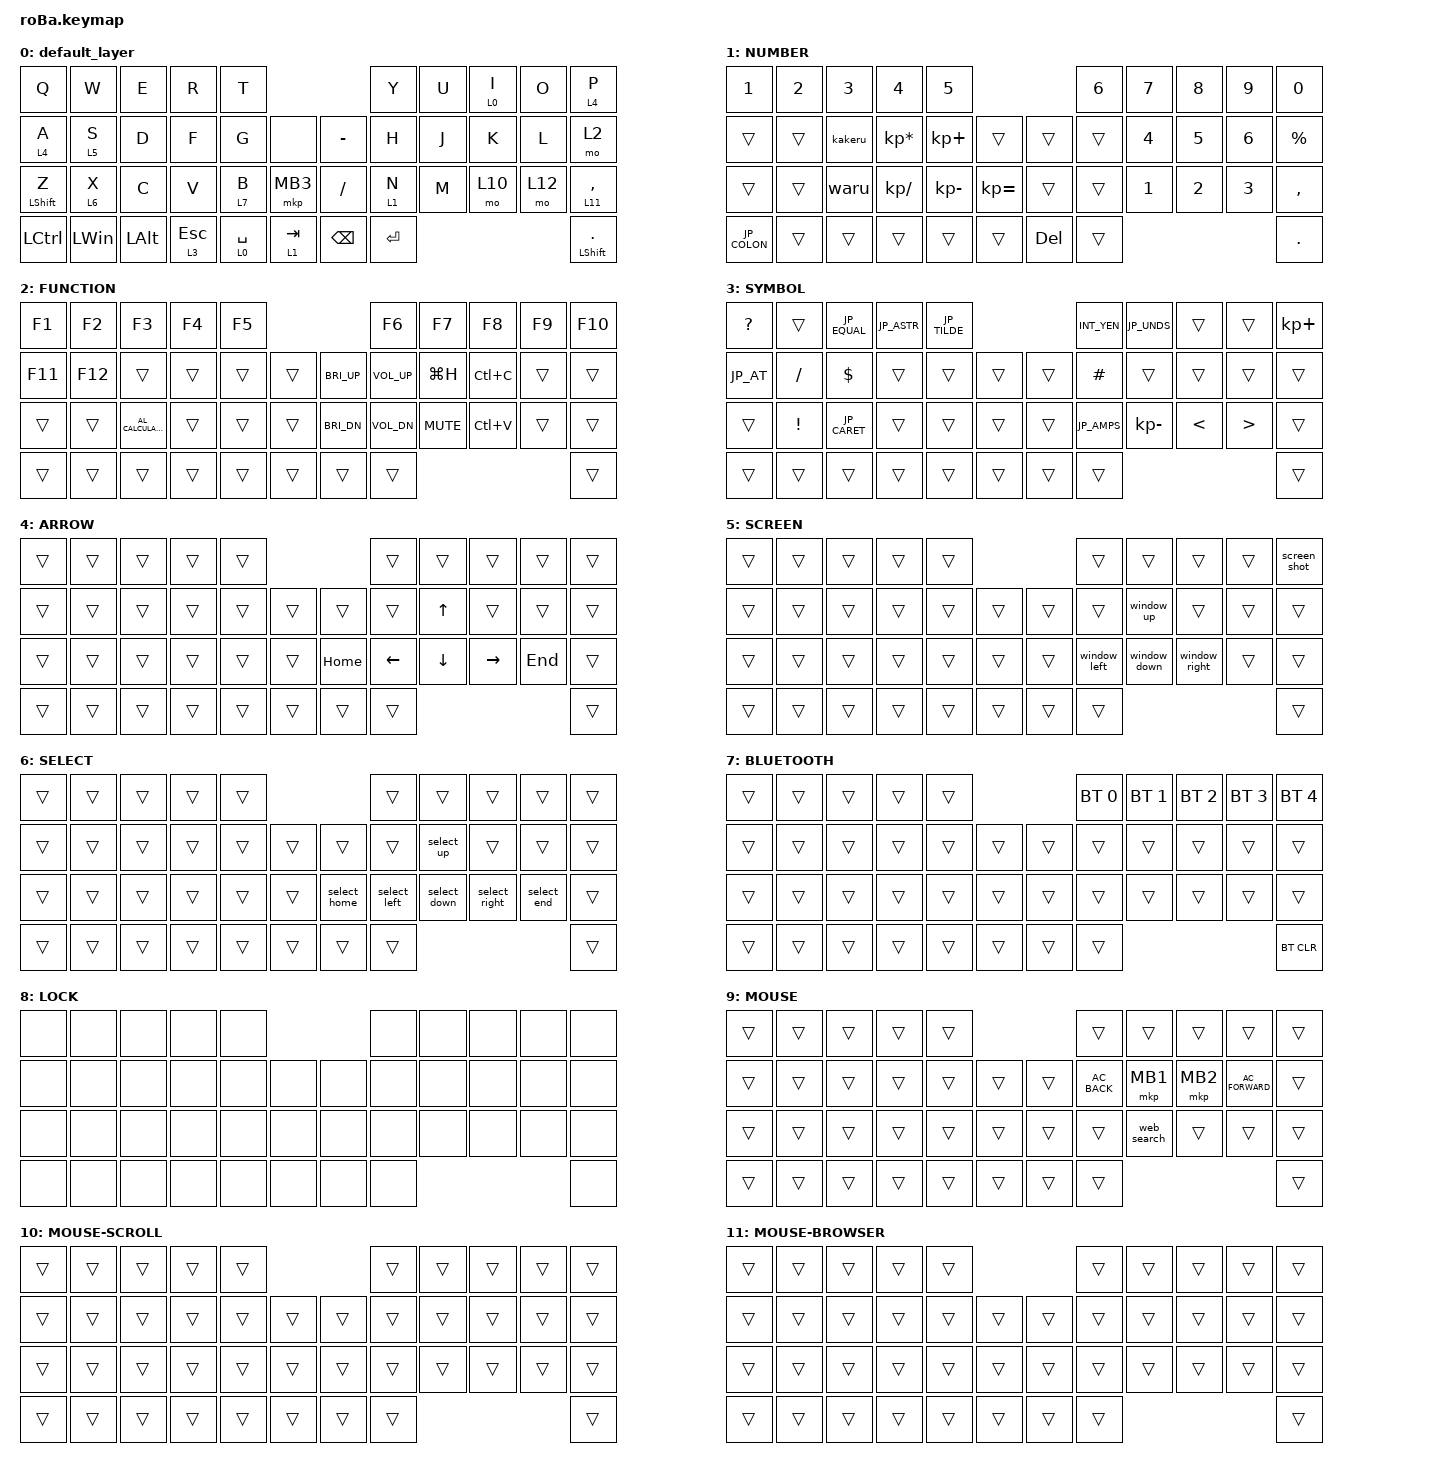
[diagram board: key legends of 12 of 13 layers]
#include <behaviors.dtsi>
#include <dt-bindings/zmk/bt.h>
#include <dt-bindings/zmk/keys.h>
#include <dt-bindings/zmk/pointing.h>

// OS側が日本語(JIS)キーボードとして認識している前提で、狙った記号が
// 出力されるように変換したキーコード。左辺の文字を出したい場合、
// 素直な同名キーコード(US配列前提)ではなく右辺を送る必要がある。

#define JP_AT      LEFT_BRACKET      // @
#define JP_DQT     LS(N2)            // "
#define JP_SQT     LS(N7)            // '
#define JP_GRAVE   LEFT_BRACE        // `
#define JP_COLON   SINGLE_QUOTE      // :
#define JP_ASTR    DOUBLE_QUOTES     // *
#define JP_CARET   EQUAL             // ^
#define JP_TILDE   PLUS              // ~
#define JP_EQUAL   UNDERSCORE        // =
#define JP_AMPS    CARET             // &
#define JP_UNDS    LS(INT_RO)        // _
#define JP_BSLH    INT_RO            // \ (ろキー)
#define JP_PIPE    LS(INT_YEN)       // |
#define JP_LBKT    RIGHT_BRACKET     // [
#define JP_RBKT    BACKSLASH         // ]
#define JP_LBRC    RIGHT_BRACE       // {
#define JP_RBRC    PIPE              // }
#define JP_LPAR    ASTERISK          // (
#define JP_RPAR    LEFT_PARENTHESIS  // )

&mt {
    flavor = "balanced";
    quick-tap-ms = <0>;
};

&trackball {
    scroll-layers = <10>;

    // arrows {
    //     layers = <3>;
    //     bindings =
    //         <&kp RIGHT_ARROW>,
    //         <&kp LEFT_ARROW>,
    //         <&kp UP_ARROW>,
    //         <&kp DOWN_ARROW>;
    //     tick = <10>;
    //     wait-ms = <5>;
    //     tap-ms = <5>;
    // };
};

/ {
    combos {
        compatible = "zmk,combos";

        child-lock {
            bindings = <&tog 8>;
            key-positions = <0 1 2 3>;
            timeout-ms = <100>;
        };

        single-quotes {
            bindings = <&kp JP_SQT>;
            key-positions = <5 6>;
            layers = <0 3>;
        };

        double-quotes {
            bindings = <&kp JP_DQT>;
            key-positions = <5 6 7>;
            layers = <0 3>;
        };

        back-quote {
            bindings = <&kp JP_GRAVE>;
            key-positions = <17 18>;
            layers = <0 3>;
        };

        brackets {
            bindings = <&brackets>;
            key-positions = <14 17>;
            layers = <0 3>;
        };

        parentheses {
            bindings = <&parentheses>;
            key-positions = <4 5>;
            layers = <0 3>;
        };

        braces {
            bindings = <&braces>;
            key-positions = <26 29>;
            layers = <0 3>;
        };

        muhenkan {
            bindings = <&kp INT_MUHENKAN>;
            key-positions = <27 26>;
            layers = <0>;
        };

        henkan {
            bindings = <&kp INT_HENKAN>;
            key-positions = <28 29>;
            layers = <0>;
        };

        mb3 {
            bindings = <&mkp MB3>;
            key-positions = <18 19>;
            layers = <9>;
        };

        semi-colon {
            bindings = <&kp SEMICOLON>;
            key-positions = <16 28>;
            layers = <0 3 1>;
        };

        colon {
            bindings = <&kp JP_COLON>;
            key-positions = <5 17>;
            layers = <0 3 1>;
        };

        back-slash {
            bindings = <&kp JP_BSLH>;
            key-positions = <20 32>;
            layers = <0 3 1>;
        };

        vertical-var {
            bindings = <&kp JP_PIPE>;
            key-positions = <31 19>;
            layers = <0 3 1>;
        };

        slash {
            bindings = <&kp SLASH>;
            key-positions = <18 30>;
            layers = <0 1 3>;
        };

        caret {
            bindings = <&kp JP_CARET>;
            key-positions = <17 6 19>;
            layers = <0 3 1>;
        };

        ctrl {
            bindings = <&kp RCTRL>;
            key-positions = <32 31>;
        };

        close {
            bindings = <&close>;
            key-positions = <36 3>;
        };
    };

    macros {
        brackets: brackets {
            compatible = "zmk,behavior-macro";
            #binding-cells = <0>;
            bindings = <&kp JP_LBKT &kp JP_RBKT &kp LEFT>;
            label = "BRACKETS";
        };

        braces: braces {
            compatible = "zmk,behavior-macro";
            #binding-cells = <0>;
            bindings = <&kp JP_LBRC &kp JP_RBRC &kp LEFT>;
            label = "BRACES";
        };

        parentheses: parentheses {
            compatible = "zmk,behavior-macro";
            #binding-cells = <0>;
            bindings = <&kp JP_LPAR &kp JP_RPAR &kp LEFT>;
            label = "PARENTHESES";
        };

        window_left: window_left {
            compatible = "zmk,behavior-macro";
            #binding-cells = <0>;
            bindings =
                <&macro_press>,
                <&kp LEFT_WIN>,
                <&macro_tap>,
                <&kp LEFT>,
                <&macro_release>,
                <&kp LEFT_WIN>;

            label = "WINDOW_LEFT";
        };

        window_right: window_right {
            compatible = "zmk,behavior-macro";
            #binding-cells = <0>;
            bindings =
                <&macro_press>,
                <&kp LEFT_WIN>,
                <&macro_tap>,
                <&kp RIGHT>,
                <&macro_release>,
                <&kp LEFT_WIN>;

            label = "WINDOW_RIGHT";
        };

        window_up: window_up {
            compatible = "zmk,behavior-macro";
            #binding-cells = <0>;
            bindings =
                <&macro_press>,
                <&kp LEFT_WIN>,
                <&macro_tap>,
                <&kp UP>,
                <&macro_release>,
                <&kp LEFT_WIN>;

            label = "WINDOW_UP";
        };

        window_down: window_down {
            compatible = "zmk,behavior-macro";
            #binding-cells = <0>;
            bindings =
                <&macro_press>,
                <&kp LEFT_WIN>,
                <&macro_tap>,
                <&kp DOWN>,
                <&macro_release>,
                <&kp LEFT_WIN>;

            label = "WINDOW_DOWN";
        };

        screen_shot: screen_shot {
            compatible = "zmk,behavior-macro";
            #binding-cells = <0>;
            bindings =
                <&macro_press>,
                <&kp LEFT_WIN &kp LEFT_SHIFT>,
                <&macro_tap>,
                <&kp S>,
                <&macro_release>,
                <&kp LEFT_WIN &kp LEFT_SHIFT>;

            label = "SCREEN_SHOT";
        };

        web_search: web_search {
            compatible = "zmk,behavior-macro";
            #binding-cells = <0>;

            // 右クリックメニューが開くまでの猶予を通常より長めに取る

            wait-ms = <150>;
            tap-ms = <30>;
            bindings =
                <&macro_press>,
                <&kp LSHIFT>,
                <&macro_tap>,
                <&kp F10>,
                <&macro_release>,
                <&kp LSHIFT>,
                <&macro_tap>,
                <&kp S>;

            label = "WEB_SEARCH";
        };

        vdesk_pin: vdesk_pin {
            compatible = "zmk,behavior-macro";
            #binding-cells = <0>;

            // タスクビューの描画・フォーカス確定を待つため、通常より長めに取る

            wait-ms = <200>;
            tap-ms = <30>;
            bindings =
                <&macro_tap>,
                <&kp LG(TAB) &kp LS(F10) &kp DOWN &kp DOWN &kp DOWN &kp RETURN>;

            label = "VDESK_PIN";
        };

        select_left: select_left {
            compatible = "zmk,behavior-macro";
            #binding-cells = <0>;
            bindings =
                <&macro_press>,
                <&kp LEFT_SHIFT>,
                <&macro_tap>,
                <&kp LEFT>,
                <&macro_release>,
                <&kp LEFT_SHIFT>;

            label = "SELECT_LEFT";
        };

        select_right: select_right {
            compatible = "zmk,behavior-macro";
            #binding-cells = <0>;
            bindings =
                <&macro_press>,
                <&kp LEFT_SHIFT>,
                <&macro_tap>,
                <&kp RIGHT>,
                <&macro_release>,
                <&kp LEFT_SHIFT>;

            label = "SELECT_RIGHT";
        };

        select_up: select_up {
            compatible = "zmk,behavior-macro";
            #binding-cells = <0>;
            bindings =
                <&macro_press>,
                <&kp LEFT_SHIFT>,
                <&macro_tap>,
                <&kp UP>,
                <&macro_release>,
                <&kp LEFT_SHIFT>;

            label = "SELECT_UP";
        };

        select_down: select_down {
            compatible = "zmk,behavior-macro";
            #binding-cells = <0>;
            bindings =
                <&macro_press>,
                <&kp LEFT_SHIFT>,
                <&macro_tap>,
                <&kp DOWN>,
                <&macro_release>,
                <&kp LEFT_SHIFT>;

            label = "SELECT_DOWN";
        };

        select_home: select_home {
            compatible = "zmk,behavior-macro";
            #binding-cells = <0>;
            bindings =
                <&macro_press>,
                <&kp LEFT_SHIFT>,
                <&macro_tap>,
                <&kp HOME>,
                <&macro_release>,
                <&kp LEFT_SHIFT>;

            label = "SELECT_HOME";
        };

        select_end: select_end {
            compatible = "zmk,behavior-macro";
            #binding-cells = <0>;
            bindings =
                <&macro_press>,
                <&kp LEFT_SHIFT>,
                <&macro_tap>,
                <&kp END>,
                <&macro_release>,
                <&kp LEFT_SHIFT>;

            label = "SELECT_END";
        };

        kakeru: kakeru {
            compatible = "zmk,behavior-macro";
            #binding-cells = <0>;
            bindings =
                <&macro_press>,
                <&kp LEFT_ALT>,
                <&macro_tap>,
                <&kp KP_N0 &kp KP_N2 &kp KP_N1 &kp KP_N5>,
                <&macro_release>,
                <&kp LEFT_ALT>;

            label = "KAKERU";
        };

        waru: waru {
            compatible = "zmk,behavior-macro";
            #binding-cells = <0>;
            bindings =
                <&macro_press>,
                <&kp LEFT_ALT>,
                <&macro_tap>,
                <&kp KP_N0 &kp KP_N2 &kp KP_N4 &kp KP_N7>,
                <&macro_release>,
                <&kp LEFT_ALT>;

            label = "WARU";
        };

        close: close {
            compatible = "zmk,behavior-macro";
            #binding-cells = <0>;
            bindings =
                <&macro_press>,
                <&kp LEFT_ALT>,
                <&macro_tap>,
                <&kp F4>,
                <&macro_release>,
                <&kp LEFT_ALT>;

            label = "CLOSE";
        };
    };

    keymap {
        compatible = "zmk,keymap";

        default_layer {
            bindings = <
&kp Q             &kp W         &kp E         &kp R         &kp T                                      &kp Y      &kp U  &lt 0 I  &kp O   &lt 4 P
&lt 4 A           &lt 5 S       &kp D         &kp F         &kp G        &none          &kp MINUS      &kp H      &kp J  &kp K    &kp L   &mo 2
&mt LEFT_SHIFT Z  &lt 6 X       &kp C         &kp V         &lt 7 B      &mkp MB3       &kp SLASH      &lt 1 N    &kp M  &mo 10   &mo 12  &lt 11 COMMA
&kp LCTRL         &kp LEFT_WIN  &kp LEFT_ALT  &lt 3 ESCAPE  &lt 0 SPACE  &lt 1 TAB      &kp BACKSPACE  &kp ENTER                          &mt LEFT_SHIFT PERIOD
            >;

            sensor-bindings = <&inc_dec_kp PG_UP PAGE_DOWN>;
        };

        NUMBER {
            bindings = <
&kp N1        &kp N2  &kp N3   &kp N4           &kp N5                                   &kp N6  &kp N7  &kp N8  &kp N9  &kp N0
&trans        &trans  &kakeru  &kp KP_MULTIPLY  &kp KP_PLUS   &trans            &trans   &trans  &kp N4  &kp N5  &kp N6  &kp PERCENT
&trans        &trans  &waru    &kp KP_SLASH     &kp KP_MINUS  &kp KP_EQUAL      &trans   &trans  &kp N1  &kp N2  &kp N3  &kp COMMA
&kp JP_COLON  &trans  &trans   &trans           &trans        &trans            &kp DEL  &trans                          &kp DOT
            >;
        };

        FUNCTION {
            bindings = <
&kp F1   &kp F2   &kp F3               &kp F4  &kp F5                            &kp F6        &kp F7      &kp F8  &kp F9  &kp F10
&kp F11  &kp F12  &trans               &trans  &trans  &trans      &kp C_BRI_UP  &kp C_VOL_UP  &kp LG(H)   &kp LC(C)  &trans  &trans
&trans   &trans   &kp C_AL_CALCULATOR  &trans  &trans  &trans      &kp C_BRI_DN  &kp C_VOL_DN  &kp C_MUTE  &kp LC(V)  &trans  &trans
&trans   &trans   &trans               &trans  &trans  &trans      &trans        &trans                                    &trans
            >;
        };

        SYMBOL {
            bindings = <
&kp QUESTION  &trans           &kp JP_EQUAL  &kp JP_ASTR  &kp JP_TILDE                      &kp INT_YEN  &kp JP_UNDS   &trans         &trans            &kp KP_PLUS
&kp JP_AT     &kp SLASH        &kp DOLLAR    &trans       &trans        &trans      &trans  &kp HASH     &trans        &trans         &trans            &trans
&trans        &kp EXCLAMATION  &kp JP_CARET  &trans       &trans        &trans      &trans  &kp JP_AMPS  &kp KP_MINUS  &kp LESS_THAN  &kp GREATER_THAN  &trans
&trans        &trans           &trans        &trans       &trans        &trans      &trans  &trans                                                      &trans
            >;
        };

        ARROW {
            bindings = <
&trans  &trans  &trans  &trans  &trans                        &trans    &trans    &trans     &trans   &trans
&trans  &trans  &trans  &trans  &trans  &trans      &trans    &trans    &kp UP    &trans     &trans   &trans
&trans  &trans  &trans  &trans  &trans  &trans      &kp HOME  &kp LEFT  &kp DOWN  &kp RIGHT  &kp END  &trans
&trans  &trans  &trans  &trans  &trans  &trans      &trans    &trans                                  &trans
            >;
        };

        SCREEN {
            bindings = <
&trans  &trans  &trans  &trans  &trans                      &trans        &trans        &trans         &trans  &screen_shot
&trans  &trans  &trans  &trans  &trans  &trans      &trans  &trans        &window_up    &trans         &trans  &trans
&trans  &trans  &trans  &trans  &trans  &trans      &trans  &window_left  &window_down  &window_right  &trans  &trans
&trans  &trans  &trans  &trans  &trans  &trans      &trans  &trans                                             &trans
            >;
        };

        SELECT {
            bindings = <
&trans  &trans  &trans  &trans  &trans                            &trans        &trans        &trans         &trans       &trans
&trans  &trans  &trans  &trans  &trans  &trans      &trans        &trans        &select_up    &trans         &trans       &trans
&trans  &trans  &trans  &trans  &trans  &trans      &select_home  &select_left  &select_down  &select_right  &select_end  &trans
&trans  &trans  &trans  &trans  &trans  &trans      &trans        &trans                                                  &trans
            >;
        };

        BLUETOOTH {
            bindings = <
&trans  &trans  &trans  &trans  &trans                      &bt BT_SEL 0  &bt BT_SEL 1  &bt BT_SEL 2  &bt BT_SEL 3  &bt BT_SEL 4
&trans  &trans  &trans  &trans  &trans  &trans      &trans  &trans        &trans        &trans        &trans        &trans
&trans  &trans  &trans  &trans  &trans  &trans      &trans  &trans        &trans        &trans        &trans        &trans
&trans  &trans  &trans  &trans  &trans  &trans      &trans  &trans                                                  &bt BT_CLR
            >;
        };

        LOCK {
            bindings = <
&none  &none  &none  &none  &none                    &none  &none  &none  &none  &none
&none  &none  &none  &none  &none  &none      &none  &none  &none  &none  &none  &none
&none  &none  &none  &none  &none  &none      &none  &none  &none  &none  &none  &none
&none  &none  &none  &none  &none  &none      &none  &none                       &none
            >;
        };

        MOUSE {
            bindings = <
&trans  &trans  &trans  &trans  &trans                      &trans         &trans       &trans    &trans            &trans
&trans  &trans  &trans  &trans  &trans  &trans      &trans  &kp C_AC_BACK  &mkp MB1     &mkp MB2  &kp C_AC_FORWARD  &trans
&trans  &trans  &trans  &trans  &trans  &trans      &trans  &trans         &web_search  &trans    &trans            &trans
&trans  &trans  &trans  &trans  &trans  &trans      &trans  &trans                                                  &trans
            >;
        };

        MOUSE-SCROLL {
            bindings = <
&trans  &trans  &trans  &trans  &trans                      &trans  &trans  &trans  &trans  &trans
&trans  &trans  &trans  &trans  &trans  &trans      &trans  &trans  &trans  &trans  &trans  &trans
&trans  &trans  &trans  &trans  &trans  &trans      &trans  &trans  &trans  &trans  &trans  &trans
&trans  &trans  &trans  &trans  &trans  &trans      &trans  &trans                          &trans
            >;
        };

        MOUSE-BROWSER {
            bindings = <
&trans  &trans  &trans  &trans  &trans                      &trans  &trans  &trans  &trans  &trans
&trans  &trans  &trans  &trans  &trans  &trans      &trans  &trans  &trans  &trans  &trans  &trans
&trans  &trans  &trans  &trans  &trans  &trans      &trans  &trans  &trans  &trans  &trans  &trans
&trans  &trans  &trans  &trans  &trans  &trans      &trans  &trans                          &trans
            >;
        };

        MOUSE-VERTIALDESKTOP {
            bindings = <
&trans  &trans  &trans  &trans  &trans                      &trans  &trans  &trans  &trans  &trans
&trans  &trans  &trans  &trans  &trans  &trans      &trans  &trans  &trans  &trans  &trans  &trans
&trans  &trans  &trans  &trans  &trans  &trans      &trans  &trans  &trans  &trans  &trans  &trans
&trans  &trans  &trans  &trans  &trans  &trans      &trans  &trans                          &trans
            >;
        };
    };
};
